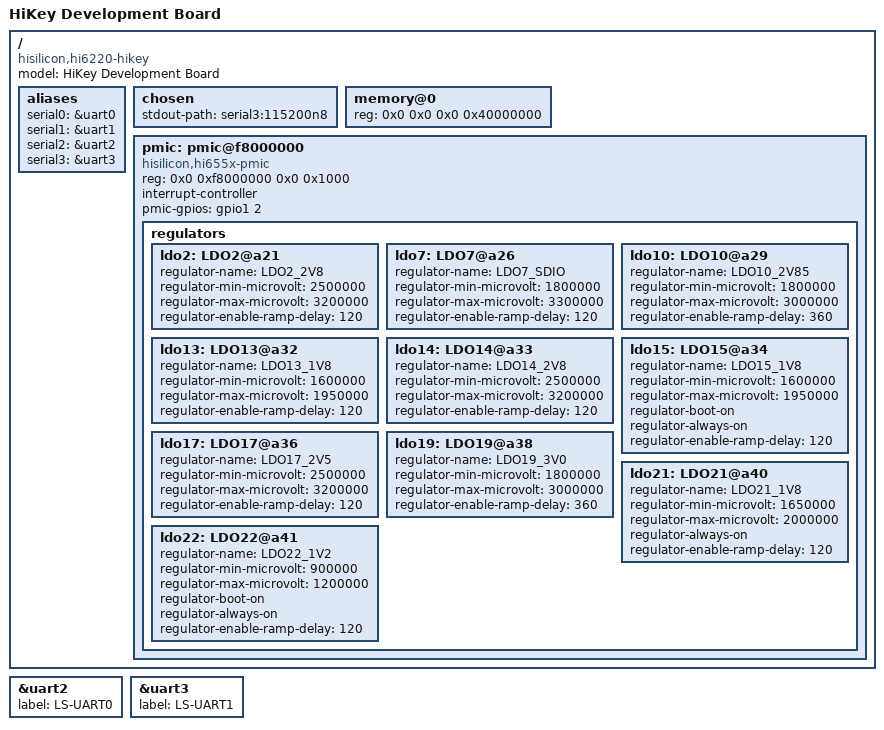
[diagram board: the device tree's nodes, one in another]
/*
 * dts file for Hisilicon HiKey Development Board
 *
 * Copyright (C) 2015, Hisilicon Ltd.
 *
 */

/dts-v1/;
#include <dt-bindings/gpio/gpio.h>

/*Reserved 1MB memory for MCU*/
/memreserve/ 0x05e00000 0x00100000;

#include "hi6220.dtsi"

/ {
	model = "HiKey Development Board";
	compatible = "hisilicon,hi6220-hikey", "hisilicon,hi6220";

	aliases {
		serial0 = &uart0; /* On board UART0 */
		serial1 = &uart1; /* BT UART */
		serial2 = &uart2; /* LS Expansion UART0 */
		serial3 = &uart3; /* LS Expansion UART1 */
	};

	chosen {
		stdout-path = "serial3:115200n8";
	};

	memory@0 {
		device_type = "memory";
		reg = <0x0 0x0 0x0 0x40000000>;
	};

	pmic: pmic@f8000000 {
		compatible = "hisilicon,hi655x-pmic";
		reg = <0x0 0xf8000000 0x0 0x1000>;
		interrupt-controller;
		#interrupt-cells = <2>;
		pmic-gpios = <&gpio1 2 GPIO_ACTIVE_HIGH>;
		status = "okay";

		regulators {
			ldo2: LDO2@a21 {
				regulator-name = "LDO2_2V8";
				regulator-min-microvolt = <2500000>;
				regulator-max-microvolt = <3200000>;
				regulator-enable-ramp-delay = <120>;
			};

			ldo7: LDO7@a26 {
				regulator-name = "LDO7_SDIO";
				regulator-min-microvolt = <1800000>;
				regulator-max-microvolt = <3300000>;
				regulator-enable-ramp-delay = <120>;
			};

			ldo10: LDO10@a29 {
				regulator-name = "LDO10_2V85";
				regulator-min-microvolt = <1800000>;
				regulator-max-microvolt = <3000000>;
				regulator-enable-ramp-delay = <360>;
			};

			ldo13: LDO13@a32 {
				regulator-name = "LDO13_1V8";
				regulator-min-microvolt = <1600000>;
				regulator-max-microvolt = <1950000>;
				regulator-enable-ramp-delay = <120>;
			};

			ldo14: LDO14@a33 {
				regulator-name = "LDO14_2V8";
				regulator-min-microvolt = <2500000>;
				regulator-max-microvolt = <3200000>;
				regulator-enable-ramp-delay = <120>;
			};

			ldo15: LDO15@a34 {
				regulator-name = "LDO15_1V8";
				regulator-min-microvolt = <1600000>;
				regulator-max-microvolt = <1950000>;
				regulator-boot-on;
				regulator-always-on;
				regulator-enable-ramp-delay = <120>;
			};

			ldo17: LDO17@a36 {
				regulator-name = "LDO17_2V5";
				regulator-min-microvolt = <2500000>;
				regulator-max-microvolt = <3200000>;
				regulator-enable-ramp-delay = <120>;
			};

			ldo19: LDO19@a38 {
				regulator-name = "LDO19_3V0";
				regulator-min-microvolt = <1800000>;
				regulator-max-microvolt = <3000000>;
				regulator-enable-ramp-delay = <360>;
			};

			ldo21: LDO21@a40 {
				regulator-name = "LDO21_1V8";
				regulator-min-microvolt = <1650000>;
				regulator-max-microvolt = <2000000>;
				regulator-always-on;
				regulator-enable-ramp-delay = <120>;
			};

			ldo22: LDO22@a41 {
				regulator-name = "LDO22_1V2";
				regulator-min-microvolt = <900000>;
				regulator-max-microvolt = <1200000>;
				regulator-boot-on;
				regulator-always-on;
				regulator-enable-ramp-delay = <120>;
			};
		};
	};
};

&uart2 {
	label = "LS-UART0";
};
&uart3 {
	label = "LS-UART1";
};
